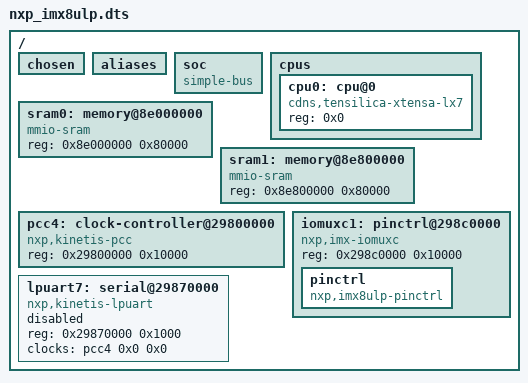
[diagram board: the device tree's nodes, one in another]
/dts-v1/;

/ {
	#address-cells = < 0x1 >;
	#size-cells = < 0x1 >;
	chosen {
	};
	aliases {
	};
	soc {
		#address-cells = < 0x1 >;
		#size-cells = < 0x1 >;
		compatible = "simple-bus";
		ranges;
	};
	cpus {
		#address-cells = < 0x1 >;
		#size-cells = < 0x0 >;
		cpu0: cpu@0 {
			device_type = "cpu";
			compatible = "cdns,tensilica-xtensa-lx7";
			reg = < 0x0 >;
		};
	};
	sram0: memory@8e000000 {
		device_type = "memory";
		compatible = "mmio-sram";
		reg = < 0x8e000000 0x80000 >;
	};
	sram1: memory@8e800000 {
		device_type = "memory";
		compatible = "mmio-sram";
		reg = < 0x8e800000 0x80000 >;
	};
	pcc4: clock-controller@29800000 {
		compatible = "nxp,kinetis-pcc";
		reg = < 0x29800000 0x10000 >;
		#clock-cells = < 0x2 >;
		phandle = < 0x1 >;
	};
	iomuxc1: pinctrl@298c0000 {
		compatible = "nxp,imx-iomuxc";
		reg = < 0x298c0000 0x10000 >;
		pinctrl: pinctrl {
			compatible = "nxp,imx8ulp-pinctrl";
		};
	};
	lpuart7: serial@29870000 {
		compatible = "nxp,kinetis-lpuart";
		reg = < 0x29870000 0x1000 >;
		clocks = < &pcc4 0x0 0x0 >;
		status = "disabled";
	};
};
